# Template register map
Vendor: VendorName Co.Ltd; Series: SeriesName; File version: 1.2
CPU: CM0+ r0p1, little endian, no MPU, no FPU, 3 interrupt priority bits
Registers are 32-bit, read-write, no defined reset value unless marked. A register's access mark holds for its fields unless they carry their own. Offsets are from the block's base; [hi:lo] are bit positions; {n}, {i} and the like mark numbered series.

## AWT
Base 0x40014C00
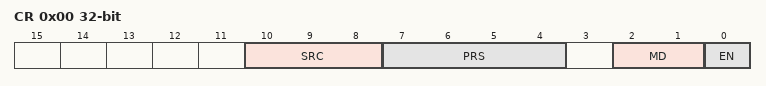
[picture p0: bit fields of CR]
0x00 CR — Control register
  [10:8] SRC, [7:4] PRS, [2:1] MD, [0] EN
0x04 ARR — Auto reload register
  [15:0] ARR
0x08 CNT ro — counter
  [15:0] CNT
0x10 IER — Interrupt enable register
  [3] UD
0x14 ISR ro — Interrupt status register
  [3] UD
0x1C ICR — Interrupt flag clear register
  [3] UD

## BTIM1 — Base Timer 1
Base 0x40014800
Same registers: BTIM2 0x40014900, BTIM3 0x40014A00
0x00 ARR — Auto Reload Register
  [15:0] ARR
0x04 CNT — Counter Register
  [15:0] CNT
0x0C ACR — Advanced Control register
  [6:4] ETRFLT
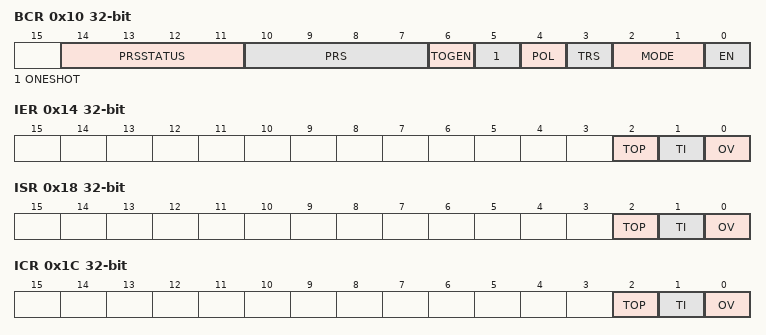
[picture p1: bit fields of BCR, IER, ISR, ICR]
0x10 BCR — Base Control register
  [14:11] PRSSTATUS ro, [10:7] PRS, [6] TOGEN, [5] ONESHOT, [4] POL, [3] TRS, [2:1] MODE, [0] EN
0x14 IER — Interrupt enable register
  [2] TOP, [1] TI, [0] OV
0x18 ISR ro — Interrupt status register
  [2] TOP, [1] TI, [0] OV
0x1C ICR — Interrupt flag clear register
  [2] TOP, [1] TI, [0] OV

## CRC
Base 0x40023000
0x00 CR — Control register
  [3:0] MODE
0x08 DR — Data register
  [7:0] DR
0x0C RESULT ro
  [15:0] RESULT16

## FLASH
Base 0x40022000
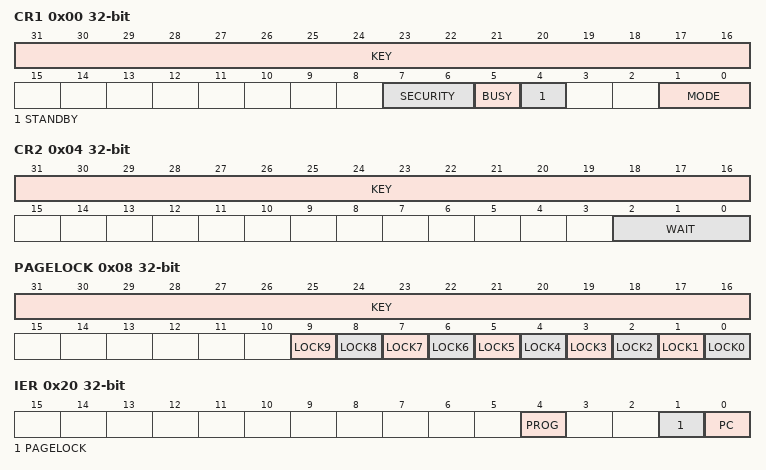
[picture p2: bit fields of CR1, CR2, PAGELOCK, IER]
0x00 CR1 — Control register1
  [31:16] KEY wo, [7:6] SECURITY ro, [5] BUSY ro, [4] STANDBY, [1:0] MODE
0x04 CR2 — Control register2
  [31:16] KEY wo, [2:0] WAIT
0x08 PAGELOCK — Page Write Erase Lock
  [31:16] KEY wo
  [n] LOCK{n} (n=0..9) — Page{4n} - {4n+3}
0x20 IER — Interrupt enable register
  [4] PROG, [1] PAGELOCK, [0] PC
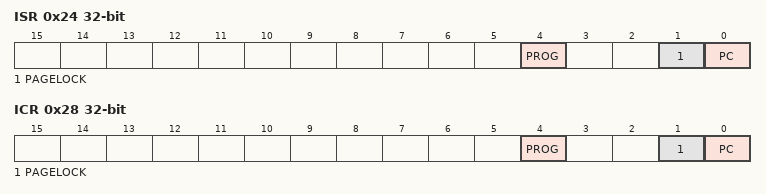
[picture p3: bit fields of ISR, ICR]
0x24 ISR ro — Interrupt status register
  [4] PROG, [1] PAGELOCK, [0] PC
0x28 ICR — Interrupt flag clear register
  [4] PROG, [1] PAGELOCK, [0] PC

## GPIOA
Base 0x48000000
Same registers: GPIOB 0x48000400
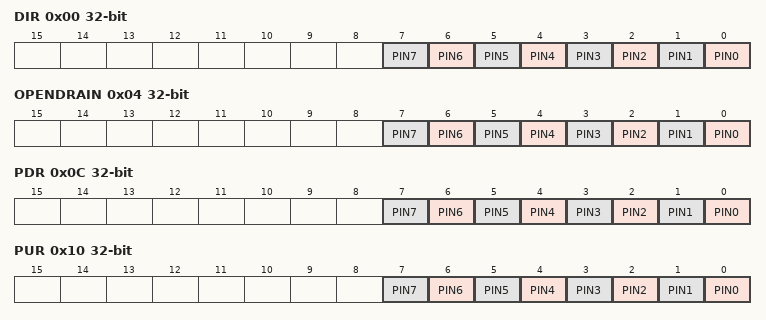
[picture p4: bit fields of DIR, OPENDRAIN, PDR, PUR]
0x00 DIR
  [n] PIN{n} (n=0..7)
0x04 OPENDRAIN
  [n] PIN{n} (n=0..7)
0x0C PDR
  [n] PIN{n} (n=0..7)
0x10 PUR
  [n] PIN{n} (n=0..7)
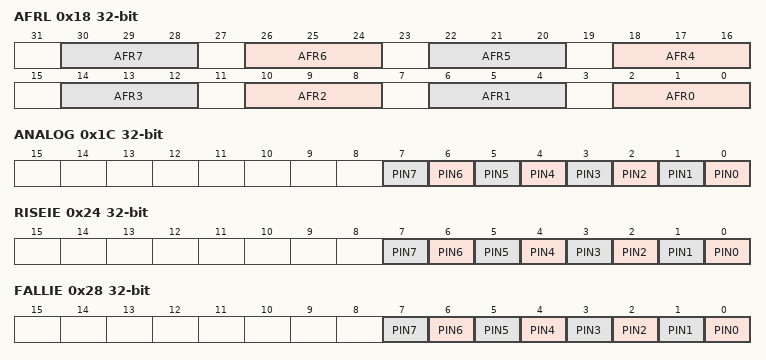
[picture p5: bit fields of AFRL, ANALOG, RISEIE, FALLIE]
0x18 AFRL
  [4n+2:4n] AFR{n} (n=0..7)
0x1C ANALOG
  [n] PIN{n} (n=0..7)
0x24 RISEIE — Interrupt enable register
  [n] PIN{n} (n=0..7)
0x28 FALLIE — Interrupt enable register
  [n] PIN{n} (n=0..7)
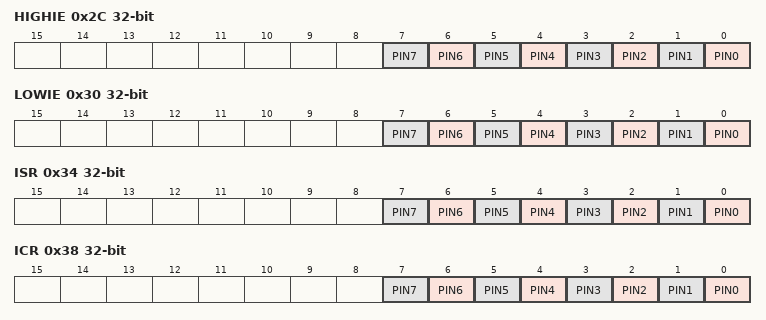
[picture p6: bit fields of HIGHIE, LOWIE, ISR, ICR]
0x2C HIGHIE — Interrupt enable register
  [n] PIN{n} (n=0..7)
0x30 LOWIE — Interrupt enable register
  [n] PIN{n} (n=0..7)
0x34 ISR — Interrupt status register
  [n] PIN{n} (n=0..7)
0x38 ICR — Interrupt flag clear register
  [n] PIN{n} (n=0..7)
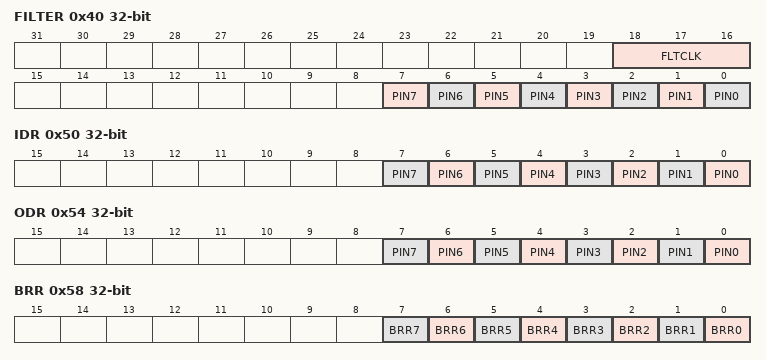
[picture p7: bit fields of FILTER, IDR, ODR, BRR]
0x40 FILTER
  [18:16] FLTCLK, [n] PIN{n} (n=0..7)
0x50 IDR
  [n] PIN{n} (n=0..7)
0x54 ODR
  [n] PIN{n} (n=0..7)
0x58 BRR
  [n] BRR{n} (n=0..7)
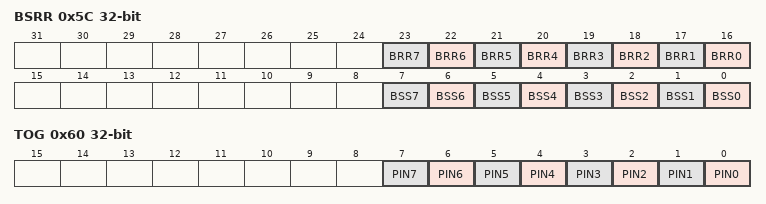
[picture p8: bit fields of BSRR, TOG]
0x5C BSRR
  [n+16] BRR{n} (n=0..7), [n] BSS{n} (n=0..7)
0x60 TOG
  [n] PIN{n} (n=0..7)

## GPIOC
Base 0x48000800
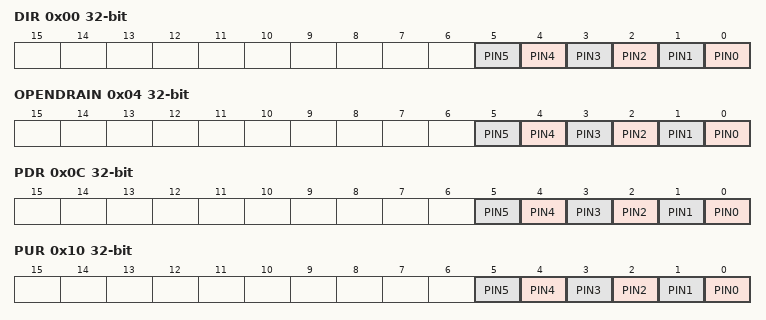
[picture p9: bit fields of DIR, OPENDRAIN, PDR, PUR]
0x00 DIR
  [n] PIN{n} (n=0..5)
0x04 OPENDRAIN
  [n] PIN{n} (n=0..5)
0x0C PDR
  [n] PIN{n} (n=0..5)
0x10 PUR
  [n] PIN{n} (n=0..5)
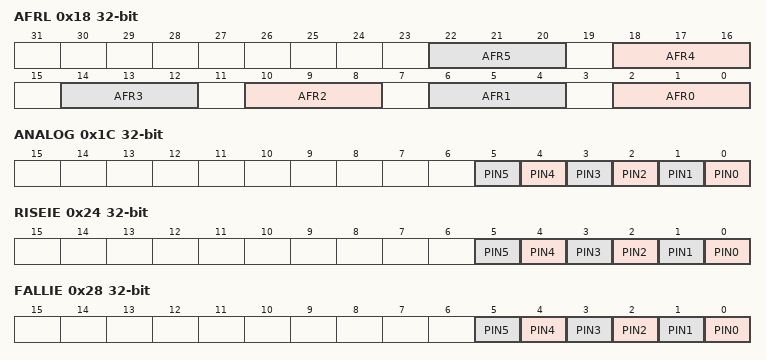
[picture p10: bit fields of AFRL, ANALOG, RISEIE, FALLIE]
0x18 AFRL
  [4n+2:4n] AFR{n} (n=0..5)
0x1C ANALOG
  [n] PIN{n} (n=0..5)
0x24 RISEIE — Interrupt enable register
  [n] PIN{n} (n=0..5)
0x28 FALLIE — Interrupt enable register
  [n] PIN{n} (n=0..5)
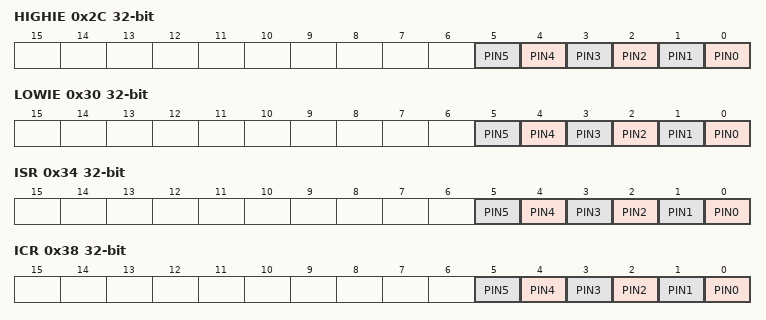
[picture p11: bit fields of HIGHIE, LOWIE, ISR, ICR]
0x2C HIGHIE — Interrupt enable register
  [n] PIN{n} (n=0..5)
0x30 LOWIE — Interrupt enable register
  [n] PIN{n} (n=0..5)
0x34 ISR — Interrupt status register
  [n] PIN{n} (n=0..5)
0x38 ICR — Interrupt flag clear register
  [n] PIN{n} (n=0..5)
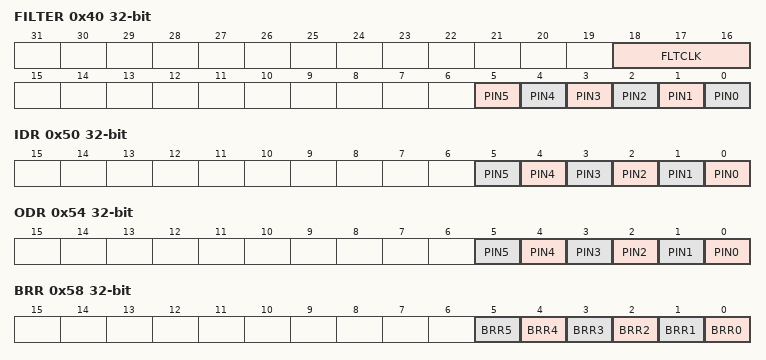
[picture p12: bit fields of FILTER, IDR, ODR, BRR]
0x40 FILTER
  [18:16] FLTCLK, [n] PIN{n} (n=0..5)
0x50 IDR
  [n] PIN{n} (n=0..5)
0x54 ODR
  [n] PIN{n} (n=0..5)
0x58 BRR
  [n] BRR{n} (n=0..5)
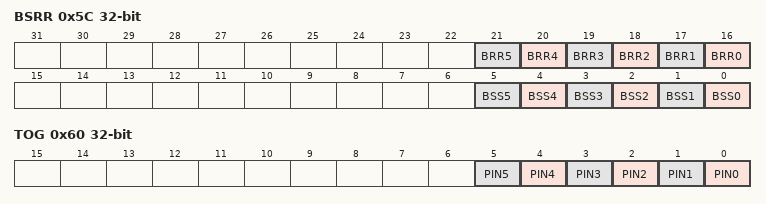
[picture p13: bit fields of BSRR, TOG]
0x5C BSRR
  [n+16] BRR{n} (n=0..5), [n] BSS{n} (n=0..5)
0x60 TOG
  [n] PIN{n} (n=0..5)

## GTIM — General Timer
Base 0x40000400
0x300 ARR — Auto Reload Register
  [15:0] ARR
0x304 CNT — Counter Register
  [15:0] CNT
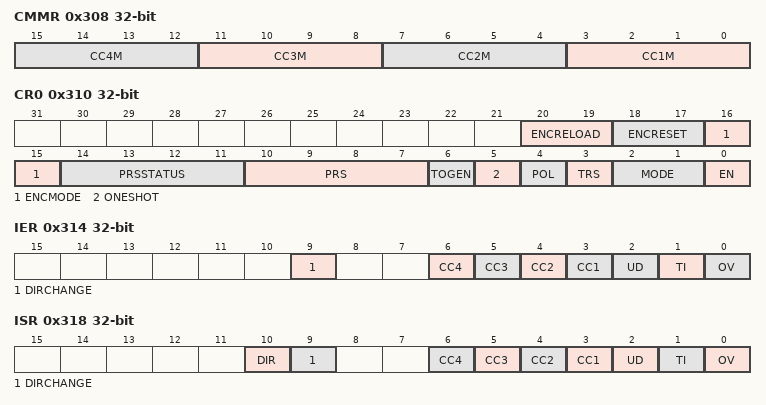
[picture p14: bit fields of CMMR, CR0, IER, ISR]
0x308 CMMR — Capture compare control Register
  [4n-1:4n-4] CC{n}M (n=1..4)
0x30C ETR — ETR Control register
  [6:4] ETRFLT
0x310 CR0 — Control register0
  [20:19] ENCRELOAD, [18:17] ENCRESET, [16:15] ENCMODE, [14:11] PRSSTATUS ro, [10:7] PRS, [6] TOGEN, [5] ONESHOT, [4] POL, [3] TRS, [2:1] MODE, [0] EN
0x314 IER — Interrupt enable register
  [9] DIRCHANGE, [n+2] CC{n} (n=1..4), [2] UD, [1] TI, [0] OV
0x318 ISR — Interrupt status register
  [10] DIR ro, [9] DIRCHANGE ro, [n+2] CC{n} ro (n=1..4), [2] UD, [1] TI, [0] OV
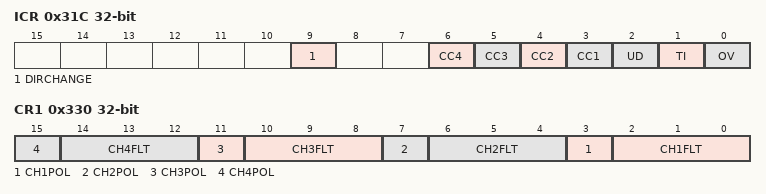
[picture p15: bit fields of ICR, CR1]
0x31C ICR — Interrupt flag clear register
  [9] DIRCHANGE, [n+2] CC{n} (n=1..4), [2] UD, [1] TI, [0] OV
{0x31C+4i} CCR{i} (i=1..4) — capture compare register
  [15:0] CCR
0x330 CR1 — Control register1
  [4n-1] CH{n}POL (n=1..4), [4n-2:4n-4] CH{n}FLT (n=1..4)
